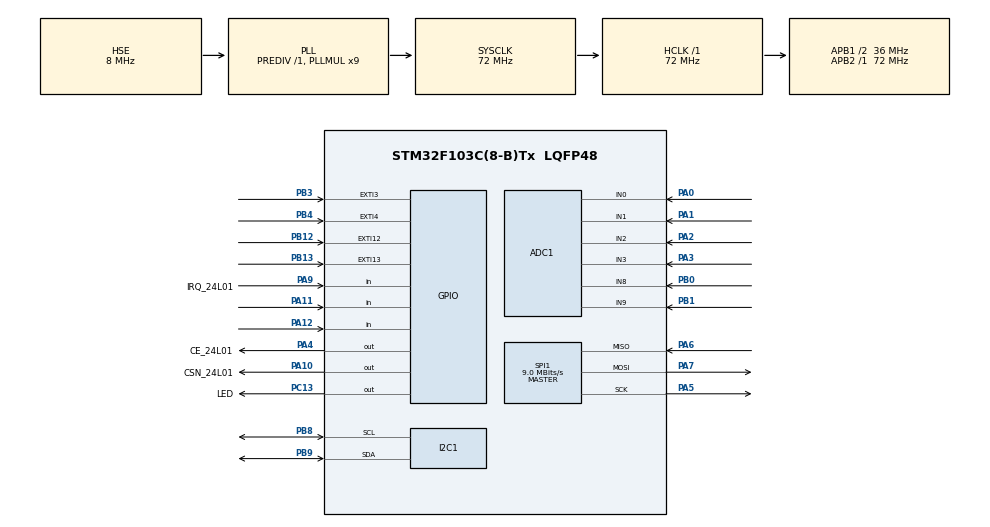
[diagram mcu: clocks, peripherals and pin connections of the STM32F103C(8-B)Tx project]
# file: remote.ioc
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ADC1.Channel-0\#ChannelRegularConversion=ADC_CHANNEL_0
ADC1.Channel-1\#ChannelRegularConversion=ADC_CHANNEL_1
ADC1.Channel-2\#ChannelRegularConversion=ADC_CHANNEL_2
ADC1.Channel-3\#ChannelRegularConversion=ADC_CHANNEL_3
ADC1.Channel-4\#ChannelRegularConversion=ADC_CHANNEL_8
ADC1.Channel-5\#ChannelRegularConversion=ADC_CHANNEL_9
ADC1.Channel-6\#ChannelRegularConversion=ADC_CHANNEL_TEMPSENSOR
ADC1.Channel-7\#ChannelRegularConversion=ADC_CHANNEL_VREFINT
ADC1.ContinuousConvMode=ENABLE
ADC1.NbrOfConversion=8
ADC1.NbrOfConversionFlag=1
ADC1.Rank-0\#ChannelRegularConversion=1
ADC1.Rank-1\#ChannelRegularConversion=2
ADC1.Rank-2\#ChannelRegularConversion=3
ADC1.Rank-3\#ChannelRegularConversion=4
ADC1.Rank-4\#ChannelRegularConversion=5
ADC1.Rank-5\#ChannelRegularConversion=6
ADC1.Rank-6\#ChannelRegularConversion=7
ADC1.Rank-7\#ChannelRegularConversion=8
ADC1.SamplingTime-0\#ChannelRegularConversion=ADC_SAMPLETIME_71CYCLES_5
ADC1.SamplingTime-1\#ChannelRegularConversion=ADC_SAMPLETIME_71CYCLES_5
ADC1.SamplingTime-2\#ChannelRegularConversion=ADC_SAMPLETIME_71CYCLES_5
ADC1.SamplingTime-3\#ChannelRegularConversion=ADC_SAMPLETIME_71CYCLES_5
ADC1.SamplingTime-4\#ChannelRegularConversion=ADC_SAMPLETIME_71CYCLES_5
ADC1.SamplingTime-5\#ChannelRegularConversion=ADC_SAMPLETIME_71CYCLES_5
ADC1.SamplingTime-6\#ChannelRegularConversion=ADC_SAMPLETIME_71CYCLES_5
ADC1.SamplingTime-7\#ChannelRegularConversion=ADC_SAMPLETIME_71CYCLES_5
ADC1.master=1
Dma.ADC1.0.Direction=DMA_PERIPH_TO_MEMORY
Dma.ADC1.0.Instance=DMA1_Channel1
Dma.ADC1.0.MemDataAlignment=DMA_MDATAALIGN_HALFWORD
Dma.ADC1.0.MemInc=DMA_MINC_ENABLE
Dma.ADC1.0.Mode=DMA_CIRCULAR
Dma.ADC1.0.PeriphDataAlignment=DMA_PDATAALIGN_HALFWORD
Dma.ADC1.0.PeriphInc=DMA_PINC_DISABLE
Dma.ADC1.0.Priority=DMA_PRIORITY_LOW
Dma.Request0=ADC1
FREERTOS.Tasks01=defaultTask,0,128,StartDefaultTask,Default,NULL,Dynamic,NULL,NULL
I2C1.I2C_Mode=I2C_Fast
Mcu.Family=STM32F1
Mcu.Name=STM32F103C(8-B)Tx
Mcu.Package=LQFP48
NVIC.DMA1_Channel1_IRQn=true\:5\:0\:false\:false\:true\:true\:false\:true\:true
NVIC.EXTI15_10_IRQn=true\:15\:0\:true\:false\:true\:true\:true\:true\:true
NVIC.EXTI3_IRQn=true\:15\:0\:true\:false\:true\:true\:true\:true\:true
NVIC.EXTI4_IRQn=true\:15\:0\:true\:false\:true\:true\:true\:true\:true
NVIC.PriorityGroup=NVIC_PRIORITYGROUP_4
NVIC.TIM4_IRQn=true\:12\:0\:true\:false\:true\:false\:false\:true\:true
NVIC.TimeBase=TIM4_IRQn
NVIC.TimeBaseIP=TIM4
PA0-WKUP.Signal=ADCx_IN0
PA1.Signal=ADCx_IN1
PA10.GPIO_Label=CSN_24L01
PA10.GPIO_Speed=GPIO_SPEED_FREQ_HIGH
PA10.PinState=GPIO_PIN_SET
PA10.Signal=GPIO_Output
PA11.GPIO_PuPd=GPIO_PULLDOWN
PA11.Signal=GPIO_Input
PA12.GPIO_PuPd=GPIO_PULLDOWN
PA12.Signal=GPIO_Input
PA13.Mode=Serial_Wire
PA13.Signal=SYS_JTMS-SWDIO
PA14.Mode=Serial_Wire
PA14.Signal=SYS_JTCK-SWCLK
PA2.Signal=ADCx_IN2
PA3.Signal=ADCx_IN3
PA4.GPIO_Label=CE_24L01
PA4.GPIO_Speed=GPIO_SPEED_FREQ_HIGH
PA4.Signal=GPIO_Output
PA5.Mode=Full_Duplex_Master
PA5.Signal=SPI1_SCK
PA6.Mode=Full_Duplex_Master
PA6.Signal=SPI1_MISO
PA7.Mode=Full_Duplex_Master
PA7.Signal=SPI1_MOSI
PA9.GPIO_Label=IRQ_24L01
PA9.GPIO_PuPd=GPIO_PULLUP
PA9.Signal=GPIO_Input
PB0.Signal=ADCx_IN8
PB1.Signal=ADCx_IN9
PB12.GPIO_ModeDefaultEXTI=GPIO_MODE_IT_FALLING
PB12.GPIO_PuPd=GPIO_PULLUP
PB12.Signal=GPXTI12
PB13.GPIO_ModeDefaultEXTI=GPIO_MODE_IT_FALLING
PB13.GPIO_PuPd=GPIO_PULLUP
PB13.Signal=GPXTI13
PB3.GPIO_ModeDefaultEXTI=GPIO_MODE_IT_FALLING
PB3.GPIO_PuPd=GPIO_PULLUP
PB3.Signal=GPXTI3
PB4.GPIO_ModeDefaultEXTI=GPIO_MODE_IT_FALLING
PB4.GPIO_PuPd=GPIO_PULLUP
PB4.Signal=GPXTI4
PB8.Mode=I2C
PB8.Signal=I2C1_SCL
PB9.Mode=I2C
PB9.Signal=I2C1_SDA
PC13-TAMPER-RTC.GPIO_Label=LED
PC13-TAMPER-RTC.GPIO_PuPd=GPIO_PULLUP
PC13-TAMPER-RTC.GPIO_Speed=GPIO_SPEED_FREQ_MEDIUM
PC13-TAMPER-RTC.Signal=GPIO_Output
PD0-OSC_IN.Mode=HSE-External-Oscillator
PD0-OSC_IN.Signal=RCC_OSC_IN
PD1-OSC_OUT.Mode=HSE-External-Oscillator
PD1-OSC_OUT.Signal=RCC_OSC_OUT
ProjectManager.HeapSize=0x800
ProjectManager.StackSize=0x800
ProjectManager.TargetToolchain=Makefile
RCC.ADCPresc=RCC_ADCPCLK2_DIV6
RCC.AHBFreq_Value=72000000
RCC.APB1CLKDivider=RCC_HCLK_DIV2
RCC.APB1Freq_Value=36000000
RCC.APB1TimFreq_Value=72000000
RCC.APB2Freq_Value=72000000
RCC.APB2TimFreq_Value=72000000
RCC.HCLKFreq_Value=72000000
RCC.PLLMUL=RCC_PLL_MUL9
RCC.PLLSourceVirtual=RCC_PLLSOURCE_HSE
RCC.SYSCLKFreq_VALUE=72000000
RCC.SYSCLKSource=RCC_SYSCLKSOURCE_PLLCLK
RCC.USBFreq_Value=72000000
SH.ADCx_IN0.0=ADC1_IN0,IN0
SH.ADCx_IN1.0=ADC1_IN1,IN1
SH.ADCx_IN2.0=ADC1_IN2,IN2
SH.ADCx_IN3.0=ADC1_IN3,IN3
SH.ADCx_IN8.0=ADC1_IN8,IN8
SH.ADCx_IN9.0=ADC1_IN9,IN9
SPI1.BaudRatePrescaler=SPI_BAUDRATEPRESCALER_8
SPI1.CLKPolarity=SPI_POLARITY_LOW
SPI1.CalculateBaudRate=9.0 MBits/s
SPI1.Direction=SPI_DIRECTION_2LINES
SPI1.Mode=SPI_MODE_MASTER
SPI1.VirtualType=VM_MASTER
VP_ADC1_TempSens_Input.Mode=IN-TempSens
VP_ADC1_Vref_Input.Mode=IN-Vrefint
VP_FREERTOS_VS_CMSIS_V1.Mode=CMSIS_V1
VP_SYS_VS_tim4.Mode=TIM4
board=custom

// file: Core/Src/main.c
/* USER CODE BEGIN Header */
/**
 ******************************************************************************
 * @file           : main.c
 * @brief          : Main program body
 ******************************************************************************
 * @attention
 *
 * Copyright (c) 2025 STMicroelectronics.
 * All rights reserved.
 *
 * This software is licensed under terms that can be found in the LICENSE file
 * in the root directory of this software component.
 * If no LICENSE file comes with this software, it is provided AS-IS.
 *
 ******************************************************************************
 */
/* USER CODE END Header */
#include "main.h"
#include "cmsis_os.h"
#include "adc.h"
#include "dma.h"
#include "i2c.h"
#include "spi.h"
#include "gpio.h"

/* USER CODE BEGIN Includes */
#include "remote.h"
#include "SEGGER_SYSVIEW.h"
/* USER CODE END Includes */

void SystemClock_Config(void);
void MX_FREERTOS_Init(void);

int main(void)
{

  /* MCU Configuration--------------------------------------------------------*/

  /* Reset of all peripherals, Initializes the Flash interface and the Systick. */
  HAL_Init();

  /* Configure the system clock */
  SystemClock_Config();

  /* Initialize all configured peripherals */
  MX_GPIO_Init();
  MX_DMA_Init();
  MX_ADC1_Init();
  MX_I2C1_Init();
  MX_SPI1_Init();
  /* USER CODE BEGIN 2 */
  // SEGGER_SYSVIEW_Conf();
  Remote_Init();
  RemoteTask_Init();
  /* USER CODE END 2 */

  /* Call init function for freertos objects (in cmsis_os2.c) */
  MX_FREERTOS_Init();

  /* Start scheduler */
  osKernelStart();

  /* We should never get here as control is now taken by the scheduler */

  /* Infinite loop */
  while (1)
  {

  }
}

void SystemClock_Config(void)
{
  RCC_OscInitTypeDef RCC_OscInitStruct = {0};
  RCC_ClkInitTypeDef RCC_ClkInitStruct = {0};
  RCC_PeriphCLKInitTypeDef PeriphClkInit = {0};

  /** Initializes the RCC Oscillators according to the specified parameters
   * in the RCC_OscInitTypeDef structure.
   */
  RCC_OscInitStruct.OscillatorType = RCC_OSCILLATORTYPE_HSE;
  RCC_OscInitStruct.HSEState = RCC_HSE_ON;
  RCC_OscInitStruct.HSEPredivValue = RCC_HSE_PREDIV_DIV1;
  RCC_OscInitStruct.HSIState = RCC_HSI_ON;
  RCC_OscInitStruct.PLL.PLLState = RCC_PLL_ON;
  RCC_OscInitStruct.PLL.PLLSource = RCC_PLLSOURCE_HSE;
  RCC_OscInitStruct.PLL.PLLMUL = RCC_PLL_MUL9;
  if (HAL_RCC_OscConfig(&RCC_OscInitStruct) != HAL_OK)
  {
    Error_Handler();
  }

  /** Initializes the CPU, AHB and APB buses clocks
   */
  RCC_ClkInitStruct.ClockType = RCC_CLOCKTYPE_HCLK | RCC_CLOCKTYPE_SYSCLK | RCC_CLOCKTYPE_PCLK1 | RCC_CLOCKTYPE_PCLK2;
  RCC_ClkInitStruct.SYSCLKSource = RCC_SYSCLKSOURCE_PLLCLK;
  RCC_ClkInitStruct.AHBCLKDivider = RCC_SYSCLK_DIV1;
  RCC_ClkInitStruct.APB1CLKDivider = RCC_HCLK_DIV2;
  RCC_ClkInitStruct.APB2CLKDivider = RCC_HCLK_DIV1;

  if (HAL_RCC_ClockConfig(&RCC_ClkInitStruct, FLASH_LATENCY_2) != HAL_OK)
  {
    Error_Handler();
  }
  PeriphClkInit.PeriphClockSelection = RCC_PERIPHCLK_ADC;
  PeriphClkInit.AdcClockSelection = RCC_ADCPCLK2_DIV6;
  if (HAL_RCCEx_PeriphCLKConfig(&PeriphClkInit) != HAL_OK)
  {
    Error_Handler();
  }
}

void HAL_TIM_PeriodElapsedCallback(TIM_HandleTypeDef *htim)
{
  if (htim->Instance == TIM4)
  {
    HAL_IncTick();
  }
}

void Error_Handler(void)
{
  __disable_irq();
  while (1)
  {
  }
}
